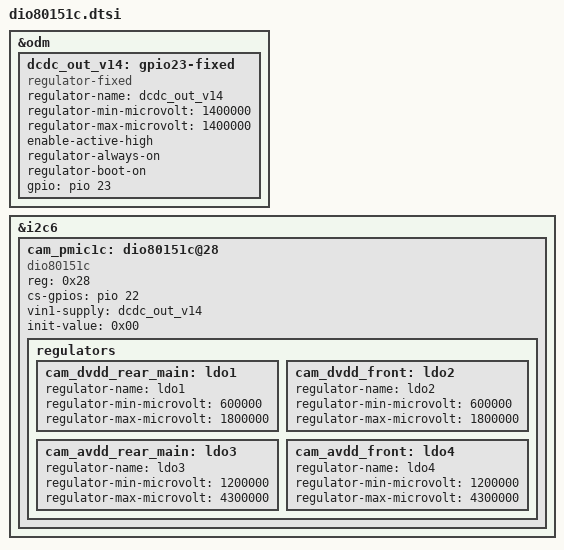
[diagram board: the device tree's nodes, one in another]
/*dio80151c dtsi*/
&odm {
        dcdc_out_v14: gpio23-fixed {
            compatible = "regulator-fixed";
            regulator-name = "dcdc_out_v14";
            regulator-min-microvolt = <1400000>;
            regulator-max-microvolt = <1400000>;
            enable-active-high;
            regulator-always-on;
            regulator-boot-on;
            gpio = <&pio 23 0x0>;
        };
};

&i2c6 {
	status = "ok";
	cam_pmic1c: dio80151c@28 {
		compatible = "dio80151c";
		reg = <0x28>;

		cs-gpios = <&pio 22 0>;
		vin1-supply = <&dcdc_out_v14>;

		init-value = <0x00>;

		regulators {
			cam_dvdd_rear_main: ldo1 {
				regulator-name = "ldo1";
				regulator-min-microvolt = <600000>;
				regulator-max-microvolt = <1800000>;
			};

			cam_dvdd_front: ldo2 {
				regulator-name = "ldo2";
				regulator-min-microvolt = <600000>;
				regulator-max-microvolt = <1800000>;
			};

			cam_avdd_rear_main: ldo3 {
				regulator-name = "ldo3";
				regulator-min-microvolt = <1200000>;
				regulator-max-microvolt = <4300000>;
			};

			cam_avdd_front: ldo4 {
				regulator-name = "ldo4";
				regulator-min-microvolt = <1200000>;
				regulator-max-microvolt = <4300000>;
			};
		};
	};
};

